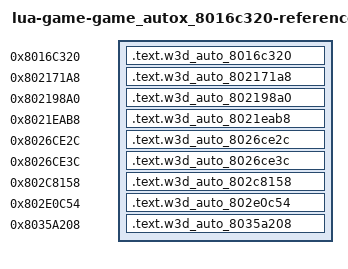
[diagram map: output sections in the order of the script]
/* Generated reference-only placements. All bodies are source-built. */
OUTPUT_FORMAT("elf32-powerpc")
OUTPUT_ARCH(powerpc)
ENTRY(w3d_auto_8016c320)
_SDA_BASE_ = 0x804b2540;
_SDA2_BASE_ = 0x804c2540;
fn_80216E7C = 0x80216e7c;
fn_8021ED0C = 0x8021ed0c;
fn_80240994 = 0x80240994;
fn_8025D588 = 0x8025d588;
SECTIONS {
  .text.w3d_auto_8016c320 0x8016c320 : { *(.text.w3d_auto_8016c320) }
  .text.w3d_auto_802171a8 0x802171a8 : { *(.text.w3d_auto_802171a8) }
  .text.w3d_auto_802198a0 0x802198a0 : { *(.text.w3d_auto_802198a0) }
  .text.w3d_auto_8021eab8 0x8021eab8 : { *(.text.w3d_auto_8021eab8) }
  .text.w3d_auto_8026ce2c 0x8026ce2c : { *(.text.w3d_auto_8026ce2c) }
  .text.w3d_auto_8026ce3c 0x8026ce3c : { *(.text.w3d_auto_8026ce3c) }
  .text.w3d_auto_802c8158 0x802c8158 : { *(.text.w3d_auto_802c8158) }
  .text.w3d_auto_802e0c54 0x802e0c54 : { *(.text.w3d_auto_802e0c54) }
  .text.w3d_auto_8035a208 0x8035a208 : { *(.text.w3d_auto_8035a208) }
  /DISCARD/ : { *(.text*) *(.rodata*) *(.data*) *(.bss*) *(.sdata*) *(.sbss*) *(.comment) }
}
